# GAP8 register map
Vendor: GreenWaves Technologies SAS; Series: GAP8; File version: 1.3.1
CPU: other r1p0, little endian, MPU, no FPU, I-cache, DTCM, false interrupt priority bits
Registers are 32-bit, read-write, reset 0x0 unless marked. A register's access mark holds for its fields unless they carry their own. Offsets are from the block's base; [hi:lo] are bit positions; 'fields as' and 'values as' point back to an identical list.

## efuse
Base 0x1A109000
0x00 cmd — EFUSE command register.
  [7:0] status_cmd — Status is not currently used EFUSE command configuration bitfield
    on read: 0=always_returns_0 (set to Always returns 0) | on write: 1=Start EFUSE read mode; 2=Start EFUSE program mode; 4=efuse_sleep_mode (set to EFUSE sleep mode.)
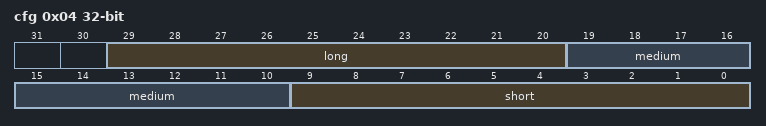
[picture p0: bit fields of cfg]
0x04 cfg — EFUSE configuration register.
  [29:20] long — EFUSE long delay configuration bitfield.
  [19:10] medium — EFUSE medium delay configuration bitfield.
  [9:0] short — EFUSE short delay configuration bitfield.
0x200 read 8-bit ro (reset mask 0xF) (alternate view of write) — EFUSE byte read command register.
  [7:0] rd_data — EFUSE byte data read at address (base+RegId*4). RegId goes from 0 to 0x7F.
0x200 write 8-bit wo (reset mask 0xF) (alternate view of read) — EFUSE byte bit index write command register.
  [7:0] wr_data_bit_idx — EFUSE bit index to burn to value 1 of the byte at address (base+RegId*4). RegId goes from 0 to 0x7F.

## spim0 — SPI Master Channel 0
Base 0x1A102080
Same registers: spim1 0x1A102100
0x00 rx_saddr — uDMA RX SPIM buffer base address configuration register.
  [15:0] rx_saddr — RX buffer base address bitfield: - Read: returns value of the buffer pointer until transfer is finished. Else returns 0. - Write: sets RX buffer base address
0x04 rx_size — uDMA RX SPIM buffer size configuration register.
  [16:0] rx_size — RX buffer size bitfield in bytes. (128kBytes maximum) - Read: returns remaining buffer size to transfer. - Write: sets buffer size.
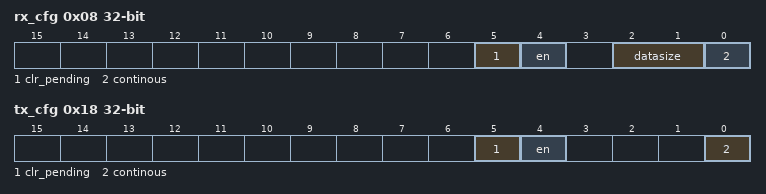
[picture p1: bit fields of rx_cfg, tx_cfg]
0x08 rx_cfg — uDMA RX SPIM stream configuration register.
  [5] clr_pending — RX channel clear and stop transfer RX transfer pending in queue status flag
    on write: 0=disable (feature is disabled); 1=stop and clear the on-going transfer | on read: 0=no pending transfer in the queue; 1=pending transfer in the queue
  [4] en — RX channel enable and start transfer bitfield This signal is used also to queue a transfer if one is already ongoing.
    0=disable (feature is disabled); 1=start (enable and start the transfer)
  [2:1] datasize — RX channel transfer size used to increment uDMA SPIM RX buffer address pointer
    0=plus_1 (+1 (8 bits)); 1=plus_2 (+2 (16 bits)); 2=plus_4 (+4 (32 bits)); 3=plus_0 (+0)
  [0] continous — RX channel continuous mode bitfield At the end of the buffer transfer, the uDMA reloads the address / buffer size and starts a new transfer.
    0=disabled (feature is disabled); 1=enabled (feature is enabled)
0x10 tx_saddr — uDMA TX SPIM buffer base address configuration register.
  [15:0] tx_saddr — TX buffer base address bitfield: - Read: returns value of the buffer pointer until transfer is finished. Else returns 0. - Write: sets buffer base address
0x14 tx_size — uDMA TX SPIM buffer size configuration register.
  [16:0] tx_size — TX buffer size bitfield in bytes. (128kBytes maximum) - Read: returns remaining buffer size to transfer. - Write: sets buffer size.
0x18 tx_cfg — uDMA TX SPIM stream configuration register.
  [5] clr_pending — TX channel clear and stop transfer bitfield TX transfer pending in queue status flag
    on write: 0=disabled (feature is disabled); 1=stop and clear the on-going transfer | on read: 0=no pending transfer in the queue; 1=pending transfer in the queue
  [4] en — TX channel enable and start transfer bitfield This signal is used also to queue a transfer if one is already ongoing.
    0=disabled (feature is disabled); 1=start (enable and start the transfer)
  [0] continous — TX channel continuous mode bitfield At the end of the buffer transfer, the uDMA reloads the address / buffer size and starts a new transfer.
    values as rx_cfg.continous
